# haltium_sysctrl register map
Vendor: Nordic Semiconductor; Series: nRFHaltium; File version: 1
Registers are 32-bit, read-write, reset 0x0 unless marked. A register's access mark holds for its fields unless they carry their own. Offsets are from the block's base; [hi:lo] are bit positions; lines under a group give offsets from that group; {n}, {i} and the like mark numbered series; 'fields as' and 'values as' point back to an identical list.

## GRTC_S — Global Real-time counter
Base 0x5F941000
0x00 TASKS_START wo — Start RTC counter
  [0] TASKS_START
    1=Trigger task
0x04 TASKS_STOP wo — Stop RTC counter
  [0] TASKS_STOP
    1=Trigger task
0x08 TASKS_CLEAR wo — Clear RTC counter
  [0] TASKS_CLEAR
    1=Trigger task
0x100 EVENTS_COMPARE — Compare event on COMPARE register match
  [0] EVENTS_COMPARE
    0=NotGenerated (Event not generated); 1=Generated (Event generated)
0x104 EVENTS_COMPARESYNC — Compare synched event on COMPARE or COMPARESYNC register value latched
  [0] EVENTS_COMPARESYNC
    values as EVENTS_COMPARE.EVENTS_COMPARE
0x200 SHORTS — Shortcuts between local events and tasks
  [0] COMPARE_CLEAR — Shortcut between event COMPARE and task CLEAR
    0=Disabled (Disable shortcut); 1=Enabled (Enable shortcut)
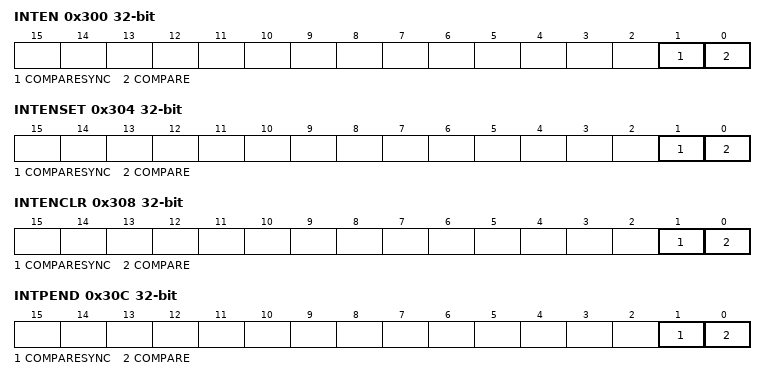
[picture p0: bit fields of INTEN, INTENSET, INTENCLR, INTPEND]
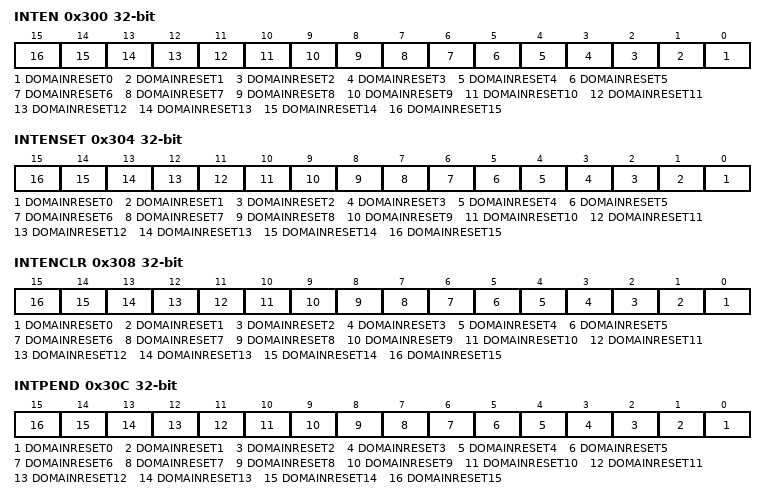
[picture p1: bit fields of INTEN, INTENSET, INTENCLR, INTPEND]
0x300 INTEN — Enable or disable interrupt
  [1] COMPARESYNC — Enable or disable interrupt for event COMPARESYNC
    0=Disabled; 1=Enabled
  [0] COMPARE — Enable or disable interrupt for event COMPARE
    0=Disabled; 1=Enabled
0x304 INTENSET — Enable interrupt
  [1] COMPARESYNC — Write '1' to enable interrupt for event COMPARESYNC
    on read: 0=Disabled (Read: Disabled); 1=Enabled (Read: Enabled) | on write: 1=Set (Enable)
  [0] COMPARE — Write '1' to enable interrupt for event COMPARE
    values as COMPARESYNC
0x308 INTENCLR — Disable interrupt
  [1] COMPARESYNC — Write '1' to disable interrupt for event COMPARESYNC
    on read: 0=Disabled (Read: Disabled); 1=Enabled (Read: Enabled) | on write: 1=Clear (Disable)
  [0] COMPARE — Write '1' to disable interrupt for event COMPARE
    values as COMPARESYNC
0x30C INTPEND ro — Pending interrupts
  [1] COMPARESYNC — Read pending status of interrupt for event COMPARESYNC
    on read: 0=NotPending (Read: Not pending); 1=Pending (Read: Pending)
  [0] COMPARE — Read pending status of interrupt for event COMPARE
    values as COMPARESYNC
0x400 COUNTERL ro — The lower 32-bits of the counter.
  [31:0] VALUE — The lower 32-bits of the current counter value.
0x404 COUNTERH ro — The most significant bits of the counter.
  [31:0] VALUE — The most significant bits of the last latched counter.
0x500 COMPAREL — The lower 32-bits of the COMPARE register.
  [31:0] VALUE — The lower 32-bits of the compare value.
0x504 COMPAREH — The most significant bits of the COMPARE register.
  [31:0] VALUE — The most significant bits of the compare value.
0x508 COMPARESYNCL — The lower 32-bits of the COMPARESYNC register.
  [31:0] VALUE — The lower 32-bits of the compare value.
0x50C COMPARESYNCH — The most significant bits of the COMPARESYNC register.
  [31:0] VALUE — The most significant bits of the compare value.

## RESETHUB_S — Reset hub
Base 0x5F943000
{0x0+4i} TASKS_RESETDOMAIN[{i}] (i=0..15) wo — Description collection: Reset the domain [n], where n is domain id.
  [0] TASKS_RESETDOMAIN — Reset the domain [n], where n is domain id.
    1=Trigger task
{0x100+4i} EVENTS_DOMAINRESET[{i}] (i=0..15) — Description collection: Domain [n] was reset, where n is domain id.
  [0] EVENTS_DOMAINRESET — Domain [n] was reset, where n is domain id.
    0=NotGenerated (Event not generated); 1=Generated (Event generated)
0x300 INTEN — Enable or disable interrupt
  [all] fields
    0=Disabled; 1=Enabled
  [n] DOMAINRESET{n} (n=0..15) — Enable or disable interrupt for event DOMAINRESET[{n}]
0x304 INTENSET — Enable interrupt
  [all] fields
    on read: 0=Disabled (Read: Disabled); 1=Enabled (Read: Enabled) | on write: 1=Set (Enable)
  [n] DOMAINRESET{n} (n=0..15) — Write '1' to enable interrupt for event DOMAINRESET[{n}]
0x308 INTENCLR — Disable interrupt
  [all] fields
    on read: 0=Disabled (Read: Disabled); 1=Enabled (Read: Enabled) | on write: 1=Clear (Disable)
  [n] DOMAINRESET{n} (n=0..15) — Write '1' to disable interrupt for event DOMAINRESET[{n}]
0x30C INTPEND ro — Pending interrupts
  [all] fields
    on read: 0=NotPending (Read: Not pending); 1=Pending (Read: Pending)
  [n] DOMAINRESET{n} (n=0..15) — Read pending status of interrupt for event DOMAINRESET[{n}]
0x400 RESETREAS group — Unspecified
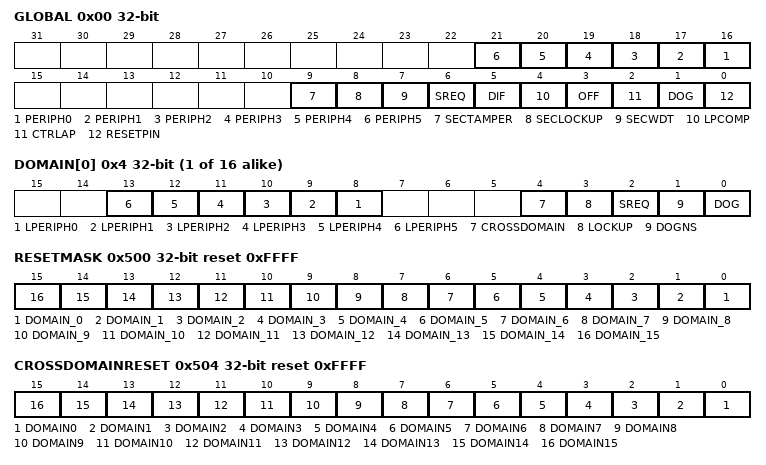
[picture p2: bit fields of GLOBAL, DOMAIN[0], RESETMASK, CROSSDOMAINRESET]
  0x00 GLOBAL write-1-clears — Global reset reason.
    [all] fields
      0=NotDetected; 1=Detected
    [n+16] PERIPH{n} (n=0..5) — Reset due to wakeup from System OFF mode when wakeup is triggered by PERIPH[{n}].
    [9] SECTAMPER — Reset due to secure domain tamper detected
    [8] SECLOCKUP — Reset due to secure domain lockup.
    [7] SECWDT — Reset due to secure domain watchdog timer detected.
    [6] SREQ — Reset due to system reset request.
    [5] DIF — Reset due to wakeup from System OFF mode when wakeup is triggered by entering the debug interface mode.
    [4] LPCOMP — Reset due to wakeup from System OFF mode when wakeup is triggered by LPCOMP (Low Power Comparator).
    [3] OFF — Reset due to wakeup from System OFF mode when wakeup is triggered by DETECT signal from GPIO.
    [2] CTRLAP — Reset from CTRL-AP detected.
    [1] DOG — Reset from the SysCtrl watchdog timer detected.
    [0] RESETPIN — Reset from pin reset detected.
  {0x4+4j} DOMAIN[{j}] (j=0..15) write-1-clears — Description collection: Reset reason for the domain[n], where n is domain id.
    [all] fields
      0=NotDetected; 1=Detected
    [n+8] LPERIPH{n} (n=0..5) — Reset due to wakeup from local domain OFF mode when wakeup is triggered by the the local PERIPH[{n}].
    [4] CROSSDOMAIN — Reset due to cross domain reset source.
    [3] LOCKUP — Reset from local CPU lockup detected
    [2] SREQ — Reset from the local soft reset request detected.
    [1] DOGNS — Reset from the local non-secure watchdog timer detected
    [0] DOG — Reset from the local watchdog timer detected
0x500 RESETMASK reset 0xFFFF — Mask the reset request for a domain by itself.
  [all] fields
    0=Mask the reset request; 1=Unmask the reset request
  [n] DOMAIN_{n} (n=0..15) — Mask the reset request for the domain[{n}], where [{n}] is domain id.
0x504 CROSSDOMAINRESET reset 0xFFFF — Enable cross domain resets.
  [all] fields
    0=Disabled (Cross domain reset disabled); 1=Enabled (Cross domain reset enabled)
  [n] DOMAIN{n} (n=0..15) — Cross domain reset enaable for DOMAIN[{n}], where [{n}] is domain id.
0x508 GPREGRET — General purpose retention register.
  [7:0] GPREGRET

## VREGSU_S — VREGSU
Base 0x5F966000
0x600 DFT group — Unspecified
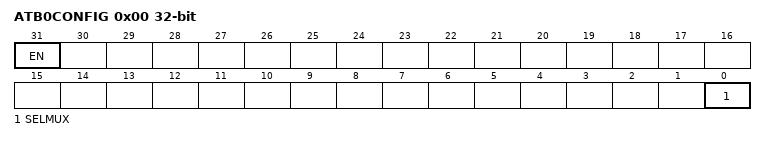
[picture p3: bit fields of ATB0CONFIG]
  0x00 ATB0CONFIG — Analog Test Bus 0 (ATB0) configuration
    [31] EN — Enable the analog test bus
      0=Disabled (Analog test bus is disabled); 1=Enabled (Analog test bus is enabled)
    [0] SELMUX — Select multiplexer for ATB0
      0=None; 1=VOUTDIV (Connects output divider to ATB)
